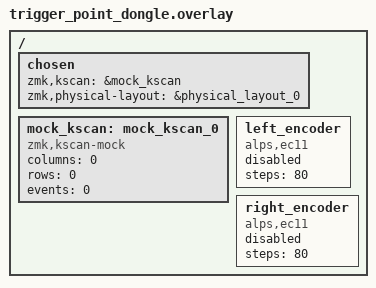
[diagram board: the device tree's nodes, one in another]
#include <dt-bindings/zmk/matrix_transform.h>
#include "trigger_point.dtsi"
#include "trigger_point-layouts.dtsi"

/ {
    chosen {
        zmk,kscan = &mock_kscan;
		zmk,physical-layout = &physical_layout_0;
    };

    mock_kscan: mock_kscan_0 {
        compatible = "zmk,kscan-mock";
        columns = <0>;
        rows = <0>;
        events = <0>;
    };

    left_encoder: left_encoder {
        compatible = "alps,ec11";
        steps = <80>;
        status = "disabled";
    };

    right_encoder: right_encoder {
        compatible = "alps,ec11";
        steps = <80>;
        status = "disabled";
    };
};
